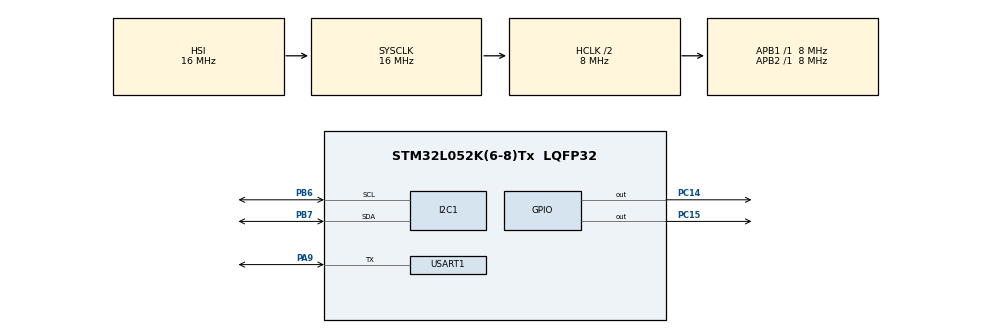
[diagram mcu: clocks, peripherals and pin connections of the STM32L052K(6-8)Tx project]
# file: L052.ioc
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I2C1.Timing=0x2000090E
Mcu.Family=STM32L0
Mcu.Name=STM32L052K(6-8)Tx
Mcu.Package=LQFP32
NVIC.TIM22_IRQn=true\:3\:0\:false\:false\:true\:false\:true\:true
NVIC.TIM6_DAC_IRQn=true\:0\:0\:false\:false\:true\:true\:true\:true
NVIC.TimeBase=TIM22_IRQn
NVIC.TimeBaseIP=TIM22
NVIC.USART1_IRQn=true\:0\:0\:false\:false\:true\:true\:true\:true
PA13.Mode=Serial_Wire
PA13.Signal=SYS_SWDIO
PA14.Mode=Serial_Wire
PA14.Signal=SYS_SWCLK
PA9.Mode=Half_duplex(single_wire_mode)
PA9.Signal=USART1_TX
PB6.Mode=I2C
PB6.Signal=I2C1_SCL
PB7.Mode=I2C
PB7.Signal=I2C1_SDA
PC14-OSC32_IN.Signal=GPIO_Output
PC15-OSC32_OUT.Signal=GPIO_Output
ProjectManager.HeapSize=0x200
ProjectManager.StackSize=0x400
ProjectManager.TargetToolchain=MDK-ARM V5.32
RCC.AHBCLKDivider=RCC_SYSCLK_DIV2
RCC.AHBFreq_Value=8000000
RCC.APB1Freq_Value=8000000
RCC.APB1TimFreq_Value=8000000
RCC.APB2Freq_Value=8000000
RCC.APB2TimFreq_Value=8000000
RCC.HCLKFreq_Value=8000000
RCC.HSI16_VALUE=16000000
RCC.HSI48_VALUE=48000000
RCC.HSI_VALUE=16000000
RCC.LSE_VALUE=32768
RCC.MSI_VALUE=2097000
RCC.SYSCLKFreq_VALUE=16000000
RCC.SYSCLKSource=RCC_SYSCLKSOURCE_HSI
RCC.VCOOutputFreq_Value=48000000
TIM6.Period=999
TIM6.Prescaler=8
USART1.BaudRate=9600
USART1.VirtualMode-Half_duplex(single_wire_mode)=VM_ASYNC
VP_RNG_VS_RNG.Mode=RNG_Activate
VP_SYS_VS_tim22.Mode=TIM22
VP_TIM6_VS_ClockSourceINT.Mode=Enable_Timer
board=custom

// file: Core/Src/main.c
/* USER CODE BEGIN Header */
/**
  ******************************************************************************
  * @file           : main.c
  * @brief          : Main program body
  ******************************************************************************
  * @attention
  *
  * Copyright (c) 2023 STMicroelectronics.
  * All rights reserved.
  *
  * This software is licensed under terms that can be found in the LICENSE file
  * in the root directory of this software component.
  * If no LICENSE file comes with this software, it is provided AS-IS.
  *
  ******************************************************************************
  */
/* USER CODE END Header */
#include "main.h"

/* USER CODE BEGIN Includes */
#include "usr_system.h"
#include "usr_lin.h"
/* USER CODE END Includes */

I2C_HandleTypeDef hi2c1;

TIM_HandleTypeDef htim6;

UART_HandleTypeDef huart1;

void SystemClock_Config(void);
static void MX_GPIO_Init(void);
static void MX_RNG_Init(void);
static void MX_TIM6_Init(void);
static void MX_USART1_UART_Init(void);
static void MX_I2C1_Init(void);

int main(void)
{

  /* MCU Configuration--------------------------------------------------------*/

  /* Reset of all peripherals, Initializes the Flash interface and the Systick. */
  HAL_Init();

  /* Configure the system clock */
  SystemClock_Config();

  /* Initialize all configured peripherals */
  MX_GPIO_Init();
  MX_RNG_Init();
  MX_TIM6_Init();
  MX_USART1_UART_Init();
  MX_I2C1_Init();
	UsrSystemInit();
  /* Infinite loop */
  while (1)
  {

    /* USER CODE BEGIN 3 */
		UsrSystemGeneral();

  }
  /* USER CODE END 3 */
}

void SystemClock_Config(void)
{
  RCC_OscInitTypeDef RCC_OscInitStruct = {0};
  RCC_ClkInitTypeDef RCC_ClkInitStruct = {0};
  RCC_PeriphCLKInitTypeDef PeriphClkInit = {0};

  /** Configure the main internal regulator output voltage
  */
  __HAL_PWR_VOLTAGESCALING_CONFIG(PWR_REGULATOR_VOLTAGE_SCALE1);

  /** Initializes the RCC Oscillators according to the specified parameters
  * in the RCC_OscInitTypeDef structure.
  */
  RCC_OscInitStruct.OscillatorType = RCC_OSCILLATORTYPE_HSI;
  RCC_OscInitStruct.HSIState = RCC_HSI_ON;
  RCC_OscInitStruct.HSICalibrationValue = RCC_HSICALIBRATION_DEFAULT;
  RCC_OscInitStruct.PLL.PLLState = RCC_PLL_ON;
  RCC_OscInitStruct.PLL.PLLSource = RCC_PLLSOURCE_HSI;
  RCC_OscInitStruct.PLL.PLLMUL = RCC_PLLMUL_3;
  RCC_OscInitStruct.PLL.PLLDIV = RCC_PLLDIV_2;
  if (HAL_RCC_OscConfig(&RCC_OscInitStruct) != HAL_OK)
  {
    Error_Handler();
  }

  /** Initializes the CPU, AHB and APB buses clocks
  */
  RCC_ClkInitStruct.ClockType = RCC_CLOCKTYPE_HCLK|RCC_CLOCKTYPE_SYSCLK
                              |RCC_CLOCKTYPE_PCLK1|RCC_CLOCKTYPE_PCLK2;
  RCC_ClkInitStruct.SYSCLKSource = RCC_SYSCLKSOURCE_HSI;
  RCC_ClkInitStruct.AHBCLKDivider = RCC_SYSCLK_DIV2;
  RCC_ClkInitStruct.APB1CLKDivider = RCC_HCLK_DIV1;
  RCC_ClkInitStruct.APB2CLKDivider = RCC_HCLK_DIV1;

  if (HAL_RCC_ClockConfig(&RCC_ClkInitStruct, FLASH_LATENCY_0) != HAL_OK)
  {
    Error_Handler();
  }
  PeriphClkInit.PeriphClockSelection = RCC_PERIPHCLK_USART1|RCC_PERIPHCLK_I2C1
                              |RCC_PERIPHCLK_USB;
  PeriphClkInit.Usart1ClockSelection = RCC_USART1CLKSOURCE_PCLK2;
  PeriphClkInit.I2c1ClockSelection = RCC_I2C1CLKSOURCE_PCLK1;
  PeriphClkInit.UsbClockSelection = RCC_USBCLKSOURCE_PLL;
  if (HAL_RCCEx_PeriphCLKConfig(&PeriphClkInit) != HAL_OK)
  {
    Error_Handler();
  }
}

static void MX_I2C1_Init(void)
{

  hi2c1.Instance = I2C1;
  hi2c1.Init.Timing = 0x2000090E;
  hi2c1.Init.OwnAddress1 = 0;
  hi2c1.Init.AddressingMode = I2C_ADDRESSINGMODE_7BIT;
  hi2c1.Init.DualAddressMode = I2C_DUALADDRESS_DISABLE;
  hi2c1.Init.OwnAddress2 = 0;
  hi2c1.Init.OwnAddress2Masks = I2C_OA2_NOMASK;
  hi2c1.Init.GeneralCallMode = I2C_GENERALCALL_DISABLE;
  hi2c1.Init.NoStretchMode = I2C_NOSTRETCH_DISABLE;
  if (HAL_I2C_Init(&hi2c1) != HAL_OK)
  {
    Error_Handler();
  }

  /** Configure Analogue filter
  */
  if (HAL_I2CEx_ConfigAnalogFilter(&hi2c1, I2C_ANALOGFILTER_ENABLE) != HAL_OK)
  {
    Error_Handler();
  }

  /** Configure Digital filter
  */
  if (HAL_I2CEx_ConfigDigitalFilter(&hi2c1, 0) != HAL_OK)
  {
    Error_Handler();
  }

}

static void MX_RNG_Init(void)
{

  /* Peripheral clock enable */
  LL_AHB1_GRP1_EnableClock(LL_AHB1_GRP1_PERIPH_RNG);

  LL_RNG_Enable(RNG);

}

static void MX_TIM6_Init(void)
{

  TIM_MasterConfigTypeDef sMasterConfig = {0};

  htim6.Instance = TIM6;
  htim6.Init.Prescaler = 8;
  htim6.Init.CounterMode = TIM_COUNTERMODE_UP;
  htim6.Init.Period = 9;
  htim6.Init.AutoReloadPreload = TIM_AUTORELOAD_PRELOAD_DISABLE;
  if (HAL_TIM_Base_Init(&htim6) != HAL_OK)
  {
    Error_Handler();
  }
  sMasterConfig.MasterOutputTrigger = TIM_TRGO_RESET;
  sMasterConfig.MasterSlaveMode = TIM_MASTERSLAVEMODE_DISABLE;
  if (HAL_TIMEx_MasterConfigSynchronization(&htim6, &sMasterConfig) != HAL_OK)
  {
    Error_Handler();
  }

}

static void MX_USART1_UART_Init(void)
{

  huart1.Instance = USART1;
  huart1.Init.BaudRate = 9600;
  huart1.Init.WordLength = UART_WORDLENGTH_8B;
  huart1.Init.StopBits = UART_STOPBITS_1;
  huart1.Init.Parity = UART_PARITY_NONE;
  huart1.Init.Mode = UART_MODE_TX_RX;
  huart1.Init.HwFlowCtl = UART_HWCONTROL_NONE;
  huart1.Init.OverSampling = UART_OVERSAMPLING_16;
  huart1.Init.OneBitSampling = UART_ONE_BIT_SAMPLE_DISABLE;
  huart1.AdvancedInit.AdvFeatureInit = UART_ADVFEATURE_NO_INIT;
  if (HAL_HalfDuplex_Init(&huart1) != HAL_OK)
  {
    Error_Handler();
  }
  /* USER CODE BEGIN USART1_Init 2 */

	// Enable the IDLE line detection interrupt
    __HAL_UART_ENABLE_IT(&huart1, UART_IT_IDLE);

  /* USER CODE END USART1_Init 2 */

}

static void MX_GPIO_Init(void)
{
  GPIO_InitTypeDef GPIO_InitStruct = {0};

  /* GPIO Ports Clock Enable */
  __HAL_RCC_GPIOC_CLK_ENABLE();
  __HAL_RCC_GPIOA_CLK_ENABLE();
  __HAL_RCC_GPIOB_CLK_ENABLE();

  /*Configure GPIO pin Output Level */
  HAL_GPIO_WritePin(GPIOC, GPIO_PIN_14|GPIO_PIN_15, GPIO_PIN_RESET);

  /*Configure GPIO pins : PC14 PC15 */
  GPIO_InitStruct.Pin = GPIO_PIN_14|GPIO_PIN_15;
  GPIO_InitStruct.Mode = GPIO_MODE_OUTPUT_PP;
  GPIO_InitStruct.Pull = GPIO_NOPULL;
  GPIO_InitStruct.Speed = GPIO_SPEED_FREQ_LOW;
  HAL_GPIO_Init(GPIOC, &GPIO_InitStruct);

}

void HAL_TIM_PeriodElapsedCallback(TIM_HandleTypeDef *htim)
{
  if (htim->Instance == TIM22) {
    HAL_IncTick();
  }
  /* USER CODE BEGIN Callback 1 */
	if (htim->Instance == TIM6) {
    systemTimer++;
  }
  /* USER CODE END Callback 1 */
}

void Error_Handler(void)
{
  __disable_irq();
  while (1)
  {
  }
}
